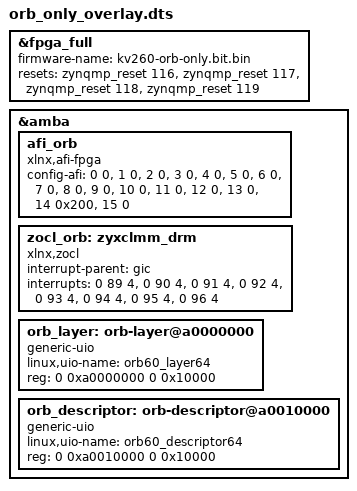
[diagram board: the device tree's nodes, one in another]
// KV260 ORB-only volatile overlay; no boot-file or persistent clock changes.
// AFI, reset and zocl layout follows AMD kria-apps-firmware KV260 examples:
// https://github.com/Xilinx/kria-apps-firmware/blob/main/boards/kv260/smartcam/kv260-smartcam.dtsi
// Control addresses must be verified against this candidate's address_map.tsv.
/dts-v1/;
/plugin/;

&fpga_full {
    #address-cells = <2>;
    #size-cells = <2>;
    firmware-name = "kv260-orb-only.bit.bin";
    resets = <&zynqmp_reset 116>, <&zynqmp_reset 117>,
             <&zynqmp_reset 118>, <&zynqmp_reset 119>;
};

&amba {
    #address-cells = <2>;
    #size-cells = <2>;
    afi_orb {
        compatible = "xlnx,afi-fpga";
        // PS AXI data widths remain 128 bits, including HP2/HP3 and HPM0.
        config-afi = <0 0>, <1 0>, <2 0>, <3 0>, <4 0>, <5 0>,
                     <6 0>, <7 0>, <8 0>, <9 0>, <10 0>, <11 0>,
                     <12 0>, <13 0>, <14 0x200>, <15 0>;
        // AFIFS SS0 (HPM0) uses the opposite encoding to the HP AFIFM ports:
        // bits[9:8]=2 selects 128-bit. XSA psu_init.c confirms mask0x300/value0x200.
    };

    zocl_orb: zyxclmm_drm {
        compatible = "xlnx,zocl";
        status = "okay";
        interrupt-parent = <&gic>;
        interrupts = <0 89 4>, <0 90 4>, <0 91 4>, <0 92 4>,
                     <0 93 4>, <0 94 4>, <0 95 4>, <0 96 4>;
    };

    orb_layer: orb-layer@a0000000 {
        compatible = "generic-uio";
        linux,uio-name = "orb60_layer64";
        reg = <0 0xa0000000 0 0x10000>;
        // Polled completion; interrupts belong to the shared zocl region.
    };

    orb_descriptor: orb-descriptor@a0010000 {
        compatible = "generic-uio";
        linux,uio-name = "orb60_descriptor64";
        reg = <0 0xa0010000 0 0x10000>;
    };
};
